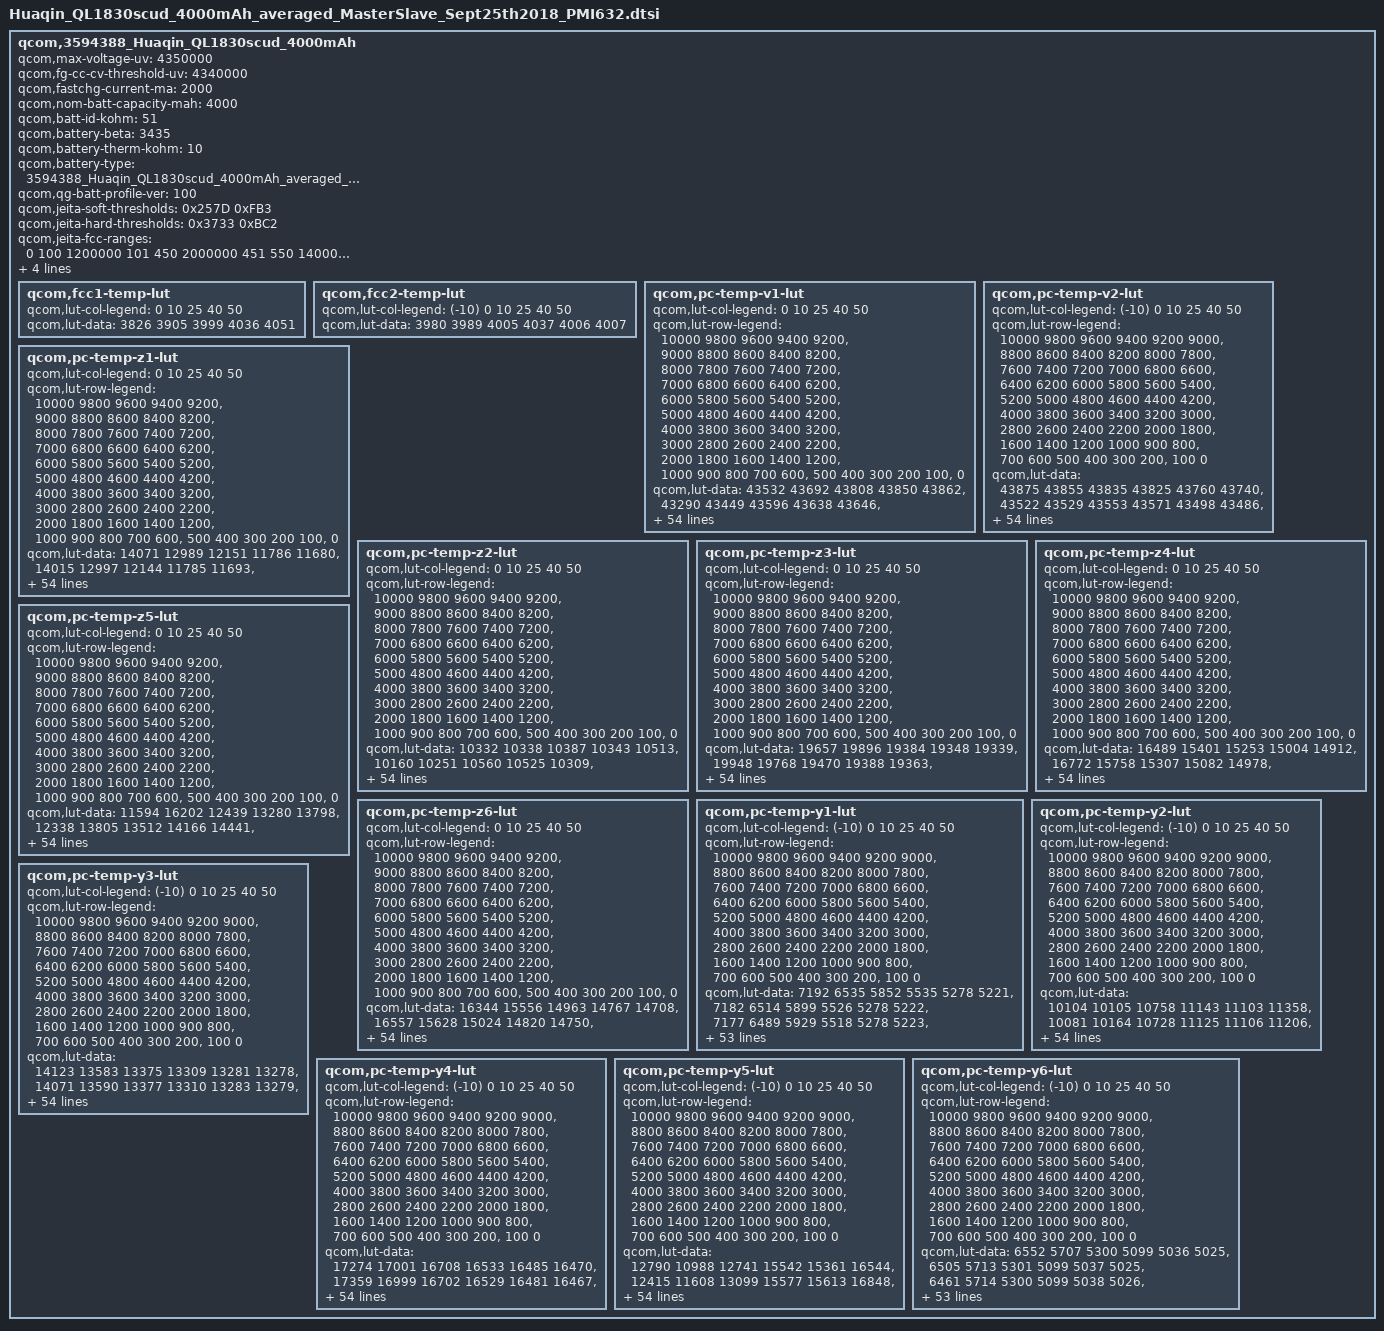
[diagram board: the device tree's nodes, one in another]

qcom,3594388_Huaqin_QL1830scud_4000mAh {
    /* 3594388_Huaqin_QL1830scud_4000mAh_averaged_MasterSlave_Sept25th2018 */
//huaqin add by tangqingyong for jeita and FV 4.35V at 20180928 start
    qcom,max-voltage-uv = <4350000>;
    qcom,fg-cc-cv-threshold-uv = <4340000>;
    qcom,fastchg-current-ma = <2000>;
    qcom,nom-batt-capacity-mah = <4000>;
//huaqin add by tangqingyong for jeita and FV 4.35V at 20180928 end
    qcom,batt-id-kohm = <51>;
    qcom,battery-beta = <3435>;
    qcom,battery-therm-kohm = <10>;
    qcom,battery-type = "3594388_Huaqin_QL1830scud_4000mAh_averaged_MasterSlave_Sept25th2018";
    qcom,qg-batt-profile-ver = <100>;
//huaqin add by tangqingyong for jeita and FV 4.35V at 20180928 start
    /* COOL = 15 DegC, WARM = 45 DegC */
    qcom,jeita-soft-thresholds = <0x257D 0xFB3>;
    /* COLD = 0 DegC, HOT = 55 DegC */
    qcom,jeita-hard-thresholds = <0x3733 0xBC2>;
    qcom,jeita-fcc-ranges = <0   100  1200000
                               101  450  2000000
                               451  550  1400000>;
    qcom,jeita-fv-ranges = <0   450  4350000
                            451 550  4100000>;
/*here step charge do not limit current*/
    qcom,step-chg-ranges = <3500000  4200000  2000000
                            4210000  4350000  2000000>;
//huaqin add by tangqingyong for jeita and FV 4.35V at 20180928 end

	qcom,fcc1-temp-lut {
		qcom,lut-col-legend = <0 10 25 40 50>;
		qcom,lut-data = <3826 3905 3999 4036 4051>;
	};

	qcom,fcc2-temp-lut {
		qcom,lut-col-legend = <(-10) 0 10 25 40 50>;
		qcom,lut-data = <3980 3989 4005 4037 4006 4007>;
	};

	qcom,pc-temp-v1-lut {
		qcom,lut-col-legend = <0 10 25 40 50>;
		qcom,lut-row-legend = <10000 9800 9600 9400 9200>,
			<9000 8800 8600 8400 8200>,
			<8000 7800 7600 7400 7200>,
			<7000 6800 6600 6400 6200>,
			<6000 5800 5600 5400 5200>,
			<5000 4800 4600 4400 4200>,
			<4000 3800 3600 3400 3200>,
			<3000 2800 2600 2400 2200>,
			<2000 1800 1600 1400 1200>,
			<1000 900 800 700 600>,
			<500 400 300 200 100>,
			<0>;
		qcom,lut-data = <43532 43692 43808 43850 43862>,
			<43290 43449 43596 43638 43646>,
			<43052 43210 43371 43421 43428>,
			<42816 42974 43140 43200 43207>,
			<42584 42741 42900 42970 42982>,
			<42355 42509 42659 42735 42752>,
			<42132 42280 42426 42503 42523>,
			<41914 42055 42196 42274 42291>,
			<41702 41835 41968 42045 42061>,
			<41497 41619 41742 41813 41833>,
			<41298 41408 41520 41583 41606>,
			<41101 41202 41304 41362 41386>,
			<40909 41005 41091 41148 41169>,
			<40714 40823 40887 40940 40959>,
			<40493 40635 40687 40737 40753>,
			<40241 40416 40490 40537 40553>,
			<40021 40182 40287 40339 40360>,
			<39866 39991 40090 40145 40174>,
			<39735 39845 39921 39966 39997>,
			<39606 39711 39781 39816 39838>,
			<39480 39571 39633 39660 39677>,
			<39356 39431 39458 39444 39462>,
			<39229 39270 39266 39172 39185>,
			<39101 39052 39055 38959 38967>,
			<38974 38830 38811 38807 38830>,
			<38843 38677 38626 38685 38719>,
			<38717 38557 38534 38588 38617>,
			<38613 38471 38468 38507 38524>,
			<38521 38416 38405 38427 38434>,
			<38446 38373 38345 38347 38340>,
			<38390 38330 38289 38272 38254>,
			<38343 38289 38233 38201 38180>,
			<38302 38249 38179 38135 38113>,
			<38267 38210 38128 38075 38050>,
			<38233 38173 38082 38021 37991>,
			<38198 38135 38038 37969 37933>,
			<38162 38099 37998 37922 37873>,
			<38119 38058 37958 37876 37811>,
			<38064 37992 37896 37812 37737>,
			<37994 37899 37800 37719 37647>,
			<37898 37793 37689 37609 37543>,
			<37751 37669 37570 37490 37424>,
			<37596 37529 37436 37355 37287>,
			<37438 37366 37275 37193 37130>,
			<37315 37231 37141 37059 37000>,
			<37227 37150 37064 36984 36924>,
			<37197 37127 37041 36964 36902>,
			<37175 37106 37027 36949 36890>,
			<37147 37089 37008 36930 36867>,
			<37075 37025 36938 36848 36769>,
			<36791 36734 36648 36540 36448>,
			<36322 36276 36194 36086 35989>,
			<35723 35685 35601 35491 35393>,
			<34901 34868 34789 34677 34575>,
			<33582 33579 33512 33402 33296>,
			<30000 30000 30000 30000 30000>;
	};

	qcom,pc-temp-v2-lut {
		qcom,lut-col-legend = <(-10) 0 10 25 40 50>;
		qcom,lut-row-legend = <10000 9800 9600 9400 9200 9000>,
			<8800 8600 8400 8200 8000 7800>,
			<7600 7400 7200 7000 6800 6600>,
			<6400 6200 6000 5800 5600 5400>,
			<5200 5000 4800 4600 4400 4200>,
			<4000 3800 3600 3400 3200 3000>,
			<2800 2600 2400 2200 2000 1800>,
			<1600 1400 1200 1000 900 800>,
			<700 600 500 400 300 200>,
			<100 0>;
		qcom,lut-data = <43875 43855 43835 43825 43760 43740>,
			<43522 43529 43553 43571 43498 43486>,
			<43194 43225 43285 43323 43245 43238>,
			<42892 42949 43031 43082 43003 43000>,
			<42611 42698 42791 42848 42772 42770>,
			<42356 42456 42555 42616 42543 42542>,
			<42138 42211 42319 42382 42311 42311>,
			<41935 41972 42086 42149 42080 42081>,
			<41699 41746 41858 41920 41853 41853>,
			<41416 41532 41635 41692 41630 41628>,
			<41177 41323 41419 41467 41409 41406>,
			<41043 41122 41214 41247 41190 41189>,
			<40932 40923 41014 41030 40975 40975>,
			<40729 40723 40817 40825 40770 40770>,
			<40343 40525 40622 40629 40574 40570>,
			<39970 40304 40415 40432 40381 40377>,
			<39720 40003 40176 40224 40183 40188>,
			<39513 39679 39925 40023 39990 40007>,
			<39335 39463 39699 39849 39819 39834>,
			<39187 39320 39492 39693 39671 39674>,
			<39044 39182 39297 39512 39505 39499>,
			<38887 39015 39112 39269 39277 39272>,
			<38730 38846 38940 39025 39033 39036>,
			<38585 38701 38787 38846 38847 38853>,
			<38447 38581 38650 38698 38695 38700>,
			<38327 38460 38525 38568 38566 38570>,
			<38232 38314 38410 38453 38454 38459>,
			<38151 38168 38305 38349 38354 38360>,
			<38077 38071 38210 38254 38263 38267>,
			<38008 38005 38123 38166 38179 38178>,
			<37945 37951 38040 38088 38101 38098>,
			<37884 37901 37954 38016 38029 38027>,
			<37826 37856 37875 37950 37959 37961>,
			<37768 37812 37820 37890 37890 37891>,
			<37711 37770 37779 37834 37823 37819>,
			<37654 37726 37741 37774 37750 37736>,
			<37597 37679 37708 37707 37662 37630>,
			<37541 37628 37674 37637 37569 37515>,
			<37485 37569 37623 37567 37484 37420>,
			<37431 37500 37550 37495 37406 37340>,
			<37375 37422 37465 37411 37321 37254>,
			<37316 37323 37366 37309 37220 37154>,
			<37253 37212 37247 37186 37105 37039>,
			<37181 37111 37093 37040 36963 36895>,
			<37095 37013 36973 36921 36859 36800>,
			<36979 36919 36898 36880 36819 36764>,
			<36914 36879 36876 36866 36809 36748>,
			<36847 36837 36852 36845 36787 36730>,
			<36761 36793 36820 36804 36752 36691>,
			<36625 36696 36730 36688 36633 36548>,
			<36374 36443 36443 36332 36277 36169>,
			<35959 35981 35942 35809 35766 35653>,
			<35346 35334 35287 35126 35103 34980>,
			<34454 34432 34374 34178 34194 34076>,
			<32936 32958 32952 32746 32751 32575>,
			<27848 27423 27941 28152 28012 27988>;
	};

	qcom,pc-temp-z1-lut {
		qcom,lut-col-legend = <0 10 25 40 50>;
		qcom,lut-row-legend = <10000 9800 9600 9400 9200>,
			<9000 8800 8600 8400 8200>,
			<8000 7800 7600 7400 7200>,
			<7000 6800 6600 6400 6200>,
			<6000 5800 5600 5400 5200>,
			<5000 4800 4600 4400 4200>,
			<4000 3800 3600 3400 3200>,
			<3000 2800 2600 2400 2200>,
			<2000 1800 1600 1400 1200>,
			<1000 900 800 700 600>,
			<500 400 300 200 100>,
			<0>;
		qcom,lut-data = <14071 12989 12151 11786 11680>,
			<14015 12997 12144 11785 11693>,
			<14021 12993 12142 11786 11693>,
			<14031 12988 12137 11785 11693>,
			<14048 12985 12127 11782 11692>,
			<14066 12988 12118 11778 11691>,
			<14066 12991 12110 11775 11691>,
			<14042 12987 12101 11772 11690>,
			<14023 12968 12093 11770 11689>,
			<14036 12955 12086 11769 11690>,
			<14069 12954 12082 11768 11691>,
			<14081 12955 12082 11768 11691>,
			<14035 12952 12082 11768 11690>,
			<13971 12929 12081 11768 11690>,
			<13945 12903 12076 11766 11689>,
			<13932 12886 12070 11764 11689>,
			<13919 12871 12067 11764 11689>,
			<13897 12867 12063 11763 11690>,
			<13871 12875 12064 11763 11691>,
			<13858 12882 12068 11764 11692>,
			<13857 12880 12073 11766 11692>,
			<13858 12873 12075 11768 11693>,
			<13857 12870 12077 11770 11695>,
			<13849 12884 12080 11772 11697>,
			<13844 12902 12082 11774 11699>,
			<13843 12904 12086 11776 11701>,
			<13842 12900 12091 11779 11703>,
			<13842 12898 12096 11783 11706>,
			<13844 12898 12101 11787 11710>,
			<13844 12900 12106 11790 11713>,
			<13843 12904 12110 11793 11715>,
			<13841 12917 12114 11797 11719>,
			<13841 12927 12118 11800 11723>,
			<13853 12927 12121 11803 11726>,
			<13866 12927 12125 11807 11728>,
			<13867 12928 12129 11810 11730>,
			<13859 12934 12135 11813 11732>,
			<13856 12942 12142 11816 11734>,
			<13871 12946 12149 11819 11737>,
			<13894 12951 12155 11823 11740>,
			<13906 12959 12162 11827 11743>,
			<13914 12974 12169 11832 11746>,
			<13914 12981 12176 11836 11749>,
			<13896 12967 12181 11839 11751>,
			<13872 12958 12191 11844 11755>,
			<13886 12972 12196 11848 11758>,
			<13871 12965 12198 11848 11757>,
			<13855 12970 12192 11849 11758>,
			<13852 12974 12190 11849 11759>,
			<13864 12971 12206 11854 11761>,
			<13904 13012 12209 11861 11769>,
			<13877 13011 12221 11869 11777>,
			<13906 13007 12238 11881 11786>,
			<13899 13083 12267 11898 11803>,
			<13899 13083 12267 11898 11803>,
			<13899 13083 12267 11898 11803>;
	};

	qcom,pc-temp-z2-lut {
		qcom,lut-col-legend = <0 10 25 40 50>;
		qcom,lut-row-legend = <10000 9800 9600 9400 9200>,
			<9000 8800 8600 8400 8200>,
			<8000 7800 7600 7400 7200>,
			<7000 6800 6600 6400 6200>,
			<6000 5800 5600 5400 5200>,
			<5000 4800 4600 4400 4200>,
			<4000 3800 3600 3400 3200>,
			<3000 2800 2600 2400 2200>,
			<2000 1800 1600 1400 1200>,
			<1000 900 800 700 600>,
			<500 400 300 200 100>,
			<0>;
		qcom,lut-data = <10332 10338 10387 10343 10513>,
			<10160 10251 10560 10525 10309>,
			<10134 10214 10958 10995 10515>,
			<10128 10194 11020 11321 10655>,
			<10129 10179 10687 11222 10641>,
			<10132 10164 10415 11021 10602>,
			<10136 10152 10391 10865 10567>,
			<10142 10147 10379 10719 10530>,
			<10147 10143 10367 10650 10505>,
			<10149 10140 10355 10704 10506>,
			<10149 10140 10349 10786 10517>,
			<10152 10142 10367 10789 10496>,
			<10191 10149 10403 10716 10407>,
			<10237 10173 10446 10673 10352>,
			<10224 10203 10555 10732 10371>,
			<10134 10234 10630 10822 10404>,
			<10073 10269 10569 10864 10406>,
			<10118 10288 10455 10884 10357>,
			<10202 10296 10429 10889 10327>,
			<10233 10302 10443 10750 10337>,
			<10239 10306 10463 10582 10360>,
			<10240 10310 10500 10627 10459>,
			<10227 10312 10542 10781 10738>,
			<10193 10313 10550 10836 10870>,
			<10177 10314 10546 10720 10645>,
			<10182 10316 10540 10578 10374>,
			<10194 10319 10518 10514 10361>,
			<10208 10322 10488 10462 10423>,
			<10229 10323 10490 10469 10503>,
			<10247 10324 10540 10645 10653>,
			<10255 10326 10578 10804 10777>,
			<10260 10333 10581 10760 10725>,
			<10268 10341 10581 10643 10562>,
			<10281 10349 10573 10604 10502>,
			<10297 10357 10545 10607 10520>,
			<10319 10363 10527 10611 10555>,
			<10349 10368 10533 10636 10642>,
			<10371 10373 10548 10692 10783>,
			<10331 10384 10569 10744 10833>,
			<10264 10401 10604 10801 10838>,
			<10282 10422 10631 10834 10835>,
			<10438 10446 10641 10833 10815>,
			<10593 10482 10652 10830 10782>,
			<10744 10551 10681 10829 10702>,
			<10485 10891 10812 10854 10652>,
			<10429 11114 10913 10817 10543>,
			<10392 11218 10892 10683 10520>,
			<10359 11280 10891 10631 10550>,
			<10349 11234 10904 10669 10582>,
			<10325 11346 10991 10827 10696>,
			<10354 11461 11235 10793 10509>,
			<10204 11466 11145 10781 10397>,
			<10038 10832 11125 10701 10359>,
			<9915 10646 11036 10604 10253>,
			<9915 10646 11036 10604 10253>,
			<9915 10646 11036 10604 10253>;
	};

	qcom,pc-temp-z3-lut {
		qcom,lut-col-legend = <0 10 25 40 50>;
		qcom,lut-row-legend = <10000 9800 9600 9400 9200>,
			<9000 8800 8600 8400 8200>,
			<8000 7800 7600 7400 7200>,
			<7000 6800 6600 6400 6200>,
			<6000 5800 5600 5400 5200>,
			<5000 4800 4600 4400 4200>,
			<4000 3800 3600 3400 3200>,
			<3000 2800 2600 2400 2200>,
			<2000 1800 1600 1400 1200>,
			<1000 900 800 700 600>,
			<500 400 300 200 100>,
			<0>;
		qcom,lut-data = <19657 19896 19384 19348 19339>,
			<19948 19768 19470 19388 19363>,
			<20037 19767 19513 19422 19399>,
			<20067 19806 19539 19446 19424>,
			<20071 19828 19568 19466 19435>,
			<20073 19832 19585 19484 19442>,
			<20071 19835 19581 19500 19443>,
			<20059 19836 19574 19517 19442>,
			<20048 19836 19571 19525 19440>,
			<20048 19836 19566 19508 19435>,
			<20051 19834 19560 19483 19425>,
			<20050 19829 19549 19476 19412>,
			<20007 19819 19536 19481 19393>,
			<19955 19786 19531 19481 19380>,
			<19981 19756 19538 19461 19376>,
			<20132 19744 19542 19436 19373>,
			<20234 19735 19529 19430 19369>,
			<20168 19728 19507 19428 19362>,
			<20046 19719 19493 19424 19356>,
			<20009 19713 19483 19405 19352>,
			<20016 19714 19479 19385 19349>,
			<20029 19718 19492 19394 19356>,
			<20063 19725 19515 19426 19384>,
			<20132 19763 19523 19438 19398>,
			<20173 19806 19525 19423 19379>,
			<20183 19812 19526 19401 19352>,
			<20190 19808 19518 19384 19340>,
			<20186 19804 19501 19369 19333>,
			<20164 19793 19489 19365 19332>,
			<20137 19778 19480 19377 19370>,
			<20116 19764 19475 19394 19411>,
			<20094 19751 19488 19410 19411>,
			<20070 19742 19509 19428 19403>,
			<20040 19738 19515 19432 19395>,
			<20009 19735 19515 19425 19384>,
			<19979 19731 19515 19415 19377>,
			<19948 19725 19510 19409 19377>,
			<19907 19719 19501 19404 19377>,
			<19788 19714 19496 19399 19377>,
			<19641 19708 19492 19395 19372>,
			<19619 19699 19488 19392 19367>,
			<19736 19683 19483 19392 19369>,
			<19761 19660 19477 19393 19371>,
			<19681 19625 19468 19391 19367>,
			<19393 19528 19442 19382 19355>,
			<19344 19468 19414 19364 19344>,
			<19340 19432 19415 19356 19345>,
			<19334 19418 19398 19355 19336>,
			<19332 19362 19397 19341 19328>,
			<19331 19366 19384 19327 19324>,
			<19340 19400 19338 19333 19335>,
			<19345 19383 19328 19321 19345>,
			<19349 19330 19327 19327 19341>,
			<19355 19330 19324 19324 19343>,
			<19355 19330 19324 19324 19343>,
			<19355 19330 19324 19324 19343>;
	};

	qcom,pc-temp-z4-lut {
		qcom,lut-col-legend = <0 10 25 40 50>;
		qcom,lut-row-legend = <10000 9800 9600 9400 9200>,
			<9000 8800 8600 8400 8200>,
			<8000 7800 7600 7400 7200>,
			<7000 6800 6600 6400 6200>,
			<6000 5800 5600 5400 5200>,
			<5000 4800 4600 4400 4200>,
			<4000 3800 3600 3400 3200>,
			<3000 2800 2600 2400 2200>,
			<2000 1800 1600 1400 1200>,
			<1000 900 800 700 600>,
			<500 400 300 200 100>,
			<0>;
		qcom,lut-data = <16489 15401 15253 15004 14912>,
			<16772 15758 15307 15082 14978>,
			<16538 15761 15262 15049 14960>,
			<16308 15603 15209 15007 14934>,
			<16155 15455 15142 14963 14905>,
			<16023 15360 15080 14916 14872>,
			<15915 15281 15036 14870 14845>,
			<15826 15212 14998 14818 14823>,
			<15749 15152 14962 14786 14804>,
			<15670 15102 14929 14775 14785>,
			<15595 15059 14899 14768 14770>,
			<15561 15025 14872 14759 14768>,
			<15558 15002 14848 14733 14771>,
			<15555 14983 14825 14716 14773>,
			<15516 14971 14792 14720 14764>,
			<15375 14964 14771 14726 14748>,
			<15282 14959 14775 14720 14738>,
			<15309 14950 14786 14705 14731>,
			<15361 14924 14782 14696 14725>,
			<15373 14890 14762 14700 14716>,
			<15318 14862 14751 14712 14710>,
			<15235 14835 14753 14739 14722>,
			<15143 14825 14760 14790 14779>,
			<15031 14844 14783 14832 14827>,
			<14965 14875 14866 14870 14859>,
			<14939 14895 14919 14895 14880>,
			<14922 14914 14916 14895 14881>,
			<14918 14922 14910 14892 14873>,
			<14916 14915 14903 14886 14859>,
			<14915 14902 14891 14856 14801>,
			<14912 14890 14875 14816 14738>,
			<14910 14878 14842 14778 14719>,
			<14907 14866 14801 14739 14709>,
			<14908 14851 14777 14726 14706>,
			<14909 14834 14760 14724 14707>,
			<14910 14822 14751 14724 14709>,
			<14915 14811 14748 14725 14711>,
			<14923 14804 14746 14728 14716>,
			<15018 14801 14749 14734 14722>,
			<15155 14799 14766 14751 14735>,
			<15159 14798 14778 14763 14744>,
			<14989 14797 14771 14756 14737>,
			<14928 14797 14763 14745 14727>,
			<14940 14798 14761 14744 14732>,
			<15037 14783 14741 14731 14728>,
			<15053 14788 14720 14710 14704>,
			<15052 14820 14705 14702 14689>,
			<15052 14828 14706 14680 14673>,
			<15044 14883 14693 14676 14660>,
			<15039 14876 14714 14701 14674>,
			<15035 14851 14797 14733 14701>,
			<15046 14880 14816 14752 14694>,
			<15057 14947 14821 14748 14701>,
			<15063 14956 14832 14755 14701>,
			<15063 14956 14832 14755 14701>,
			<15063 14956 14832 14755 14701>;
	};

	qcom,pc-temp-z5-lut {
		qcom,lut-col-legend = <0 10 25 40 50>;
		qcom,lut-row-legend = <10000 9800 9600 9400 9200>,
			<9000 8800 8600 8400 8200>,
			<8000 7800 7600 7400 7200>,
			<7000 6800 6600 6400 6200>,
			<6000 5800 5600 5400 5200>,
			<5000 4800 4600 4400 4200>,
			<4000 3800 3600 3400 3200>,
			<3000 2800 2600 2400 2200>,
			<2000 1800 1600 1400 1200>,
			<1000 900 800 700 600>,
			<500 400 300 200 100>,
			<0>;
		qcom,lut-data = <11594 16202 12439 13280 13798>,
			<12338 13805 13512 14166 14441>,
			<12643 13595 14108 14968 15902>,
			<12811 13973 14517 15446 16951>,
			<12919 14317 15174 15985 17391>,
			<12994 14537 15679 16768 17731>,
			<13046 14735 15782 17806 17931>,
			<13079 15000 15808 19396 18088>,
			<13116 15351 15943 20335 18182>,
			<13223 15731 16253 20415 18291>,
			<13395 16220 16625 20399 18421>,
			<13454 16702 17098 21091 18110>,
			<13173 16758 17632 24575 16890>,
			<12828 16337 18290 26593 16121>,
			<13200 15984 20139 24440 16376>,
			<15124 16156 21442 21550 16832>,
			<16435 16607 20576 21621 16999>,
			<15668 16959 18952 23391 16945>,
			<14254 17255 18655 24448 17001>,
			<13845 17696 19373 22646 17349>,
			<14174 18563 20574 20453 18060>,
			<14814 20387 25748 25729 21894>,
			<16405 23435 33409 40473 33257>,
			<20053 35040 36099 45848 38667>,
			<24073 47609 37156 36535 30605>,
			<29151 48538 37572 25309 20036>,
			<33938 44480 33934 20707 16808>,
			<35638 39858 27221 17661 15163>,
			<36400 35388 23423 16658 14800>,
			<36580 31040 20837 16802 17625>,
			<35355 28379 19705 17420 21310>,
			<32731 26386 20882 19607 22963>,
			<30281 25423 23392 23792 24070>,
			<27906 25586 25827 26393 24866>,
			<25700 25975 28728 28117 25598>,
			<24014 26221 30343 29044 26276>,
			<22446 26355 30320 28824 27106>,
			<20729 26507 29989 28091 28141>,
			<18108 27042 29380 26870 28073>,
			<15582 27998 27967 23900 24186>,
			<15415 28276 26512 21658 20759>,
			<17853 26526 25386 21411 20720>,
			<18578 24460 24378 21250 20901>,
			<17343 22897 23032 20497 19649>,
			<13553 21347 23052 20435 18369>,
			<12790 18779 21766 19755 18029>,
			<12691 15897 22041 18912 18868>,
			<12588 15219 19269 20045 18655>,
			<12592 13668 19537 18483 19514>,
			<12663 13825 17904 15823 17277>,
			<12898 14811 13783 14376 15113>,
			<12801 13979 13125 13275 15562>,
			<12658 12617 12921 13318 14752>,
			<12561 12469 12644 12952 14451>,
			<12561 12469 12644 12952 14451>,
			<12561 12469 12644 12952 14451>;
	};

	qcom,pc-temp-z6-lut {
		qcom,lut-col-legend = <0 10 25 40 50>;
		qcom,lut-row-legend = <10000 9800 9600 9400 9200>,
			<9000 8800 8600 8400 8200>,
			<8000 7800 7600 7400 7200>,
			<7000 6800 6600 6400 6200>,
			<6000 5800 5600 5400 5200>,
			<5000 4800 4600 4400 4200>,
			<4000 3800 3600 3400 3200>,
			<3000 2800 2600 2400 2200>,
			<2000 1800 1600 1400 1200>,
			<1000 900 800 700 600>,
			<500 400 300 200 100>,
			<0>;
		qcom,lut-data = <16344 15556 14963 14767 14708>,
			<16557 15628 15024 14820 14750>,
			<16483 15623 15031 14826 14761>,
			<16399 15561 15026 14826 14765>,
			<16326 15499 15007 14819 14760>,
			<16252 15454 14986 14806 14749>,
			<16192 15414 14965 14794 14739>,
			<16140 15379 14943 14781 14730>,
			<16095 15349 14924 14767 14720>,
			<16059 15323 14906 14754 14709>,
			<16029 15302 14889 14741 14698>,
			<15998 15283 14871 14730 14689>,
			<15958 15260 14854 14721 14681>,
			<15926 15230 14841 14713 14673>,
			<15923 15204 14831 14703 14666>,
			<15930 15191 14822 14695 14659>,
			<15935 15182 14814 14688 14651>,
			<15914 15171 14807 14681 14644>,
			<15870 15154 14798 14674 14638>,
			<15834 15137 14784 14666 14632>,
			<15806 15127 14777 14661 14627>,
			<15781 15120 14783 14674 14638>,
			<15761 15118 14797 14716 14680>,
			<15744 15146 14818 14737 14703>,
			<15732 15184 14855 14743 14703>,
			<15725 15197 14876 14745 14702>,
			<15719 15204 14871 14742 14698>,
			<15711 15207 14861 14733 14692>,
			<15699 15200 14852 14725 14685>,
			<15685 15187 14843 14718 14681>,
			<15674 15175 14835 14712 14676>,
			<15663 15165 14828 14706 14669>,
			<15652 15156 14822 14699 14661>,
			<15640 15148 14816 14694 14655>,
			<15627 15141 14811 14689 14650>,
			<15614 15135 14806 14686 14647>,
			<15599 15131 14801 14683 14648>,
			<15585 15127 14797 14682 14650>,
			<15573 15125 14798 14682 14652>,
			<15563 15124 14804 14687 14655>,
			<15555 15122 14808 14691 14656>,
			<15548 15117 14805 14689 14655>,
			<15537 15110 14799 14685 14652>,
			<15506 15095 14794 14684 14652>,
			<15402 15043 14775 14674 14645>,
			<15383 15017 14752 14656 14629>,
			<15378 15013 14746 14649 14623>,
			<15374 15010 14737 14639 14611>,
			<15371 15006 14732 14629 14601>,
			<15375 15009 14736 14633 14606>,
			<15385 15021 14750 14652 14625>,
			<15400 15031 14756 14657 14630>,
			<15421 15040 14762 14661 14633>,
			<15446 15058 14771 14666 14638>,
			<15446 15058 14771 14666 14638>,
			<15446 15058 14771 14666 14638>;
	};

	qcom,pc-temp-y1-lut {
		qcom,lut-col-legend = <(-10) 0 10 25 40 50>;
		qcom,lut-row-legend = <10000 9800 9600 9400 9200 9000>,
			<8800 8600 8400 8200 8000 7800>,
			<7600 7400 7200 7000 6800 6600>,
			<6400 6200 6000 5800 5600 5400>,
			<5200 5000 4800 4600 4400 4200>,
			<4000 3800 3600 3400 3200 3000>,
			<2800 2600 2400 2200 2000 1800>,
			<1600 1400 1200 1000 900 800>,
			<700 600 500 400 300 200>,
			<100 0>;
		qcom,lut-data = <7192 6535 5852 5535 5278 5221>,
			<7182 6514 5899 5526 5278 5222>,
			<7177 6489 5929 5518 5278 5223>,
			<7176 6464 5946 5509 5277 5223>,
			<7176 6443 5953 5502 5277 5223>,
			<7176 6430 5955 5495 5276 5223>,
			<7179 6424 5942 5488 5275 5222>,
			<7184 6421 5922 5482 5274 5221>,
			<7180 6421 5919 5476 5272 5220>,
			<7164 6425 5922 5469 5271 5220>,
			<7152 6429 5924 5464 5270 5219>,
			<7150 6428 5917 5461 5269 5219>,
			<7150 6426 5906 5459 5268 5219>,
			<7159 6424 5904 5456 5267 5218>,
			<7186 6424 5905 5454 5266 5219>,
			<7204 6425 5906 5452 5266 5219>,
			<7193 6432 5911 5453 5267 5219>,
			<7172 6442 5917 5454 5267 5219>,
			<7168 6443 5917 5455 5268 5219>,
			<7185 6434 5917 5455 5269 5220>,
			<7200 6427 5917 5456 5270 5221>,
			<7190 6426 5917 5458 5270 5221>,
			<7168 6426 5918 5460 5271 5222>,
			<7162 6426 5920 5463 5272 5223>,
			<7161 6431 5922 5465 5274 5224>,
			<7158 6434 5923 5468 5276 5225>,
			<7146 6434 5924 5471 5278 5227>,
			<7126 6433 5924 5475 5281 5229>,
			<7120 6432 5925 5479 5283 5231>,
			<7137 6427 5930 5483 5285 5233>,
			<7154 6425 5933 5487 5288 5235>,
			<7152 6428 5938 5491 5291 5237>,
			<7149 6433 5946 5495 5293 5240>,
			<7145 6436 5947 5500 5296 5242>,
			<7140 6434 5944 5504 5299 5244>,
			<7135 6430 5942 5508 5302 5246>,
			<7131 6418 5945 5512 5304 5248>,
			<7125 6401 5950 5515 5307 5250>,
			<7116 6396 5951 5520 5309 5251>,
			<7093 6398 5951 5525 5311 5253>,
			<7075 6400 5953 5529 5313 5255>,
			<7071 6397 5957 5532 5316 5256>,
			<7072 6392 5960 5537 5319 5258>,
			<7098 6399 5964 5549 5323 5259>,
			<7112 6427 5969 5553 5327 5264>,
			<7124 6440 5987 5554 5329 5266>,
			<7148 6435 5999 5555 5329 5267>,
			<7173 6454 5998 5560 5330 5266>,
			<7159 6487 5983 5563 5330 5266>,
			<7152 6469 5981 5565 5330 5268>,
			<7141 6454 5988 5570 5334 5271>,
			<7149 6472 5999 5582 5341 5277>,
			<7193 6492 6003 5604 5351 5286>,
			<7242 6491 6028 5629 5364 5297>,
			<7242 6491 6028 5629 5364 5297>,
			<7242 6491 6028 5629 5364 5297>;
	};

	qcom,pc-temp-y2-lut {
		qcom,lut-col-legend = <(-10) 0 10 25 40 50>;
		qcom,lut-row-legend = <10000 9800 9600 9400 9200 9000>,
			<8800 8600 8400 8200 8000 7800>,
			<7600 7400 7200 7000 6800 6600>,
			<6400 6200 6000 5800 5600 5400>,
			<5200 5000 4800 4600 4400 4200>,
			<4000 3800 3600 3400 3200 3000>,
			<2800 2600 2400 2200 2000 1800>,
			<1600 1400 1200 1000 900 800>,
			<700 600 500 400 300 200>,
			<100 0>;
		qcom,lut-data = <10104 10105 10758 11143 11103 11358>,
			<10081 10164 10728 11125 11106 11206>,
			<10078 10212 10708 11101 11113 11097>,
			<10090 10248 10695 11076 11120 11026>,
			<10113 10270 10689 11055 11127 10986>,
			<10144 10278 10687 11044 11130 10974>,
			<10182 10264 10692 11040 11129 11012>,
			<10234 10242 10703 11038 11128 11071>,
			<10320 10243 10714 11045 11137 11082>,
			<10486 10284 10727 11077 11171 11081>,
			<10587 10346 10734 11109 11197 11081>,
			<10573 10477 10723 11150 11206 11104>,
			<10547 10634 10707 11187 11213 11142>,
			<10553 10660 10725 11184 11219 11155>,
			<10636 10632 10830 11160 11226 11155>,
			<10747 10612 10896 11149 11237 11161>,
			<10885 10634 10894 11176 11342 11211>,
			<11026 10685 10891 11217 11495 11297>,
			<11013 10743 10893 11247 11547 11380>,
			<10669 10820 10910 11276 11570 11475>,
			<10377 10903 10933 11285 11578 11519>,
			<10149 11002 10970 11250 11503 11450>,
			<9789 11095 11016 11212 11388 11331>,
			<9695 11107 11054 11222 11355 11260>,
			<9687 11066 11087 11261 11344 11206>,
			<9682 11036 11119 11294 11340 11184>,
			<9677 11067 11159 11316 11383 11305>,
			<9672 11121 11194 11337 11449 11473>,
			<9670 11132 11201 11365 11486 11485>,
			<9669 11117 11200 11396 11517 11415>,
			<9668 11095 11201 11422 11552 11374>,
			<9667 11066 11209 11446 11611 11446>,
			<9666 11015 11219 11461 11666 11566>,
			<9666 10853 11216 11457 11662 11637>,
			<9665 10208 11192 11445 11618 11689>,
			<9664 9725 11166 11431 11582 11709>,
			<9663 9694 11140 11411 11547 11587>,
			<9662 9681 11114 11390 11502 11411>,
			<9662 9674 11094 11372 11466 11369>,
			<9661 9670 11079 11353 11432 11365>,
			<9661 9667 11059 11335 11414 11371>,
			<9661 9665 11023 11321 11409 11385>,
			<9660 9663 10976 11291 11402 11391>,
			<9660 9661 10921 11230 11373 11252>,
			<9660 9660 10839 11200 11205 11020>,
			<9659 9660 10844 11189 11181 11019>,
			<9659 9660 10803 11198 11172 11019>,
			<9659 9659 10773 11187 11140 11035>,
			<9658 9658 10738 11162 11150 11042>,
			<9658 9658 10712 11129 11144 11045>,
			<9657 9657 10618 11140 11138 10951>,
			<9657 9656 10406 11056 11093 10841>,
			<9655 9655 9737 10942 11015 10827>,
			<9653 9655 9679 10857 10946 10820>,
			<9653 9655 9679 10857 10946 10820>,
			<9653 9655 9679 10857 10946 10820>;
	};

	qcom,pc-temp-y3-lut {
		qcom,lut-col-legend = <(-10) 0 10 25 40 50>;
		qcom,lut-row-legend = <10000 9800 9600 9400 9200 9000>,
			<8800 8600 8400 8200 8000 7800>,
			<7600 7400 7200 7000 6800 6600>,
			<6400 6200 6000 5800 5600 5400>,
			<5200 5000 4800 4600 4400 4200>,
			<4000 3800 3600 3400 3200 3000>,
			<2800 2600 2400 2200 2000 1800>,
			<1600 1400 1200 1000 900 800>,
			<700 600 500 400 300 200>,
			<100 0>;
		qcom,lut-data = <14123 13583 13375 13309 13281 13278>,
			<14071 13590 13377 13310 13283 13279>,
			<14004 13594 13382 13311 13284 13281>,
			<13939 13595 13387 13312 13286 13282>,
			<13888 13596 13392 13313 13287 13284>,
			<13867 13595 13393 13314 13289 13285>,
			<13876 13585 13393 13315 13290 13286>,
			<13889 13569 13393 13317 13291 13288>,
			<13877 13573 13393 13317 13293 13289>,
			<13782 13608 13392 13316 13298 13290>,
			<13693 13633 13392 13316 13301 13291>,
			<13652 13588 13398 13318 13302 13293>,
			<13623 13514 13408 13320 13302 13295>,
			<13619 13502 13409 13320 13303 13296>,
			<13628 13528 13409 13320 13307 13298>,
			<13635 13545 13408 13320 13310 13299>,
			<13588 13526 13406 13320 13309 13301>,
			<13502 13492 13403 13321 13306 13303>,
			<13471 13477 13399 13324 13304 13302>,
			<13462 13473 13390 13328 13300 13297>,
			<13459 13467 13381 13330 13297 13291>,
			<13466 13446 13373 13324 13294 13287>,
			<13480 13418 13365 13315 13291 13283>,
			<13483 13412 13361 13311 13290 13281>,
			<13478 13413 13358 13309 13288 13281>,
			<13473 13413 13356 13307 13287 13280>,
			<13471 13397 13353 13307 13287 13282>,
			<13470 13368 13351 13306 13287 13284>,
			<13473 13361 13351 13307 13287 13284>,
			<13487 13361 13354 13308 13287 13281>,
			<13505 13361 13356 13308 13288 13279>,
			<13523 13364 13352 13309 13290 13280>,
			<13544 13371 13347 13310 13292 13281>,
			<13567 13380 13346 13312 13292 13283>,
			<13591 13395 13350 13314 13291 13284>,
			<13618 13412 13354 13314 13290 13285>,
			<13647 13428 13360 13314 13288 13284>,
			<13679 13446 13366 13312 13288 13282>,
			<13716 13467 13366 13312 13288 13282>,
			<13761 13495 13366 13311 13288 13282>,
			<13810 13527 13365 13311 13288 13283>,
			<13859 13559 13365 13311 13289 13285>,
			<13911 13597 13364 13311 13289 13285>,
			<13962 13659 13357 13309 13289 13282>,
			<13998 13717 13356 13306 13288 13284>,
			<13908 13657 13344 13310 13292 13289>,
			<13877 13680 13350 13312 13298 13290>,
			<13953 13728 13356 13316 13299 13296>,
			<14022 13800 13370 13322 13308 13299>,
			<14103 13872 13380 13330 13308 13297>,
			<14194 13952 13374 13316 13298 13290>,
			<14304 14047 13378 13319 13299 13290>,
			<14508 14176 13425 13335 13307 13295>,
			<15053 14321 13506 13352 13314 13305>,
			<15053 14321 13506 13352 13314 13305>,
			<15053 14321 13506 13352 13314 13305>;
	};

	qcom,pc-temp-y4-lut {
		qcom,lut-col-legend = <(-10) 0 10 25 40 50>;
		qcom,lut-row-legend = <10000 9800 9600 9400 9200 9000>,
			<8800 8600 8400 8200 8000 7800>,
			<7600 7400 7200 7000 6800 6600>,
			<6400 6200 6000 5800 5600 5400>,
			<5200 5000 4800 4600 4400 4200>,
			<4000 3800 3600 3400 3200 3000>,
			<2800 2600 2400 2200 2000 1800>,
			<1600 1400 1200 1000 900 800>,
			<700 600 500 400 300 200>,
			<100 0>;
		qcom,lut-data = <17274 17001 16708 16533 16485 16470>,
			<17359 16999 16702 16529 16481 16467>,
			<17411 17000 16699 16527 16479 16466>,
			<17438 17005 16698 16527 16479 16465>,
			<17448 17013 16697 16529 16480 16465>,
			<17449 17022 16698 16531 16483 16466>,
			<17365 17040 16700 16535 16487 16467>,
			<17229 17059 16704 16541 16492 16469>,
			<17209 17046 16711 16549 16494 16472>,
			<17278 16954 16725 16561 16495 16477>,
			<17364 16891 16733 16574 16495 16482>,
			<17456 16995 16732 16584 16503 16487>,
			<17543 17165 16729 16595 16516 16491>,
			<17512 17191 16739 16612 16525 16496>,
			<17199 17124 16789 16636 16531 16504>,
			<16969 17039 16821 16656 16539 16512>,
			<17005 16947 16793 16673 16553 16519>,
			<17076 16858 16741 16684 16572 16528>,
			<17103 16834 16700 16684 16595 16545>,
			<17104 16829 16662 16676 16627 16578>,
			<17100 16825 16637 16662 16643 16595>,
			<17085 16820 16626 16602 16599 16565>,
			<17053 16814 16618 16539 16529 16516>,
			<17030 16799 16613 16522 16502 16493>,
			<17005 16759 16610 16514 16488 16480>,
			<16990 16728 16609 16512 16483 16475>,
			<16995 16722 16610 16517 16488 16477>,
			<17004 16718 16611 16524 16497 16481>,
			<17007 16718 16610 16531 16508 16488>,
			<17004 16721 16600 16540 16522 16505>,
			<17001 16725 16593 16550 16533 16521>,
			<16999 16726 16592 16563 16540 16535>,
			<16997 16727 16592 16573 16545 16545>,
			<16998 16735 16594 16576 16547 16546>,
			<17004 16777 16604 16578 16549 16542>,
			<17014 16816 16615 16578 16550 16536>,
			<17030 16830 16627 16567 16532 16514>,
			<17054 16839 16639 16556 16507 16489>,
			<17079 16841 16645 16552 16502 16484>,
			<17106 16836 16649 16550 16501 16483>,
			<17133 16831 16651 16548 16501 16483>,
			<17159 16825 16649 16546 16502 16483>,
			<17179 16820 16645 16541 16503 16482>,
			<17185 16816 16630 16531 16488 16473>,
			<17180 16819 16625 16519 16484 16465>,
			<17028 16799 16627 16521 16489 16470>,
			<16978 16802 16640 16540 16494 16487>,
			<16985 16832 16666 16562 16517 16504>,
			<16996 16850 16688 16584 16532 16527>,
			<16996 16870 16701 16582 16531 16518>,
			<16980 16846 16690 16546 16486 16472>,
			<16961 16819 16681 16544 16483 16474>,
			<16981 16820 16730 16544 16484 16478>,
			<17167 16838 16765 16576 16510 16507>,
			<17167 16838 16765 16576 16510 16507>,
			<17167 16838 16765 16576 16510 16507>;
	};

	qcom,pc-temp-y5-lut {
		qcom,lut-col-legend = <(-10) 0 10 25 40 50>;
		qcom,lut-row-legend = <10000 9800 9600 9400 9200 9000>,
			<8800 8600 8400 8200 8000 7800>,
			<7600 7400 7200 7000 6800 6600>,
			<6400 6200 6000 5800 5600 5400>,
			<5200 5000 4800 4600 4400 4200>,
			<4000 3800 3600 3400 3200 3000>,
			<2800 2600 2400 2200 2000 1800>,
			<1600 1400 1200 1000 900 800>,
			<700 600 500 400 300 200>,
			<100 0>;
		qcom,lut-data = <12790 10988 12741 15542 15361 16544>,
			<12415 11608 13099 15577 15613 16848>,
			<12241 12235 13536 15540 15705 17012>,
			<12238 12786 13961 15447 15676 17070>,
			<12374 13180 14283 15312 15561 17055>,
			<12622 13332 14410 15150 15399 17001>,
			<14072 13206 14356 14953 15070 16863>,
			<16170 13005 14261 14707 14709 16623>,
			<16251 13360 14202 14363 14792 16306>,
			<14103 15585 14149 13867 15523 15813>,
			<12595 17095 14165 13622 15981 15429>,
			<13242 15645 14681 13636 15442 15364>,
			<14765 13265 15581 13669 14633 15458>,
			<16530 13601 16224 13634 14523 15441>,
			<19132 18560 16675 13508 14684 15147>,
			<20694 22014 17336 13515 14780 14967>,
			<18435 19733 19607 14269 14569 15012>,
			<14341 15872 22283 15704 14258 15044>,
			<13295 15199 22390 18268 14272 14909>,
			<13515 16318 20590 22543 14717 14277>,
			<13700 17111 18864 24227 15380 13906>,
			<13591 16701 17732 22994 17146 15180>,
			<13353 15997 16888 21188 19156 17016>,
			<13122 16191 16670 19870 19344 17242>,
			<12754 18422 16595 18657 18647 16837>,
			<12401 20045 16569 17901 17853 16587>,
			<12154 17942 16616 17409 17022 16741>,
			<11956 14206 16730 17137 16291 16956>,
			<11914 13222 17219 17203 16131 16681>,
			<11929 13146 18983 17437 16173 15333>,
			<11945 13117 20042 17660 16309 14551>,
			<11993 13316 18821 18049 17152 14809>,
			<12071 13681 17089 18614 18175 15374>,
			<12083 13715 16844 19710 18299 16224>,
			<12047 13310 17075 21265 18198 17690>,
			<11993 13006 17375 21645 18110 18441>,
			<11893 13062 18205 20790 18145 18404>,
			<11758 13194 19190 19676 18217 18272>,
			<11723 13329 19156 18780 18032 18055>,
			<11764 13557 18212 17926 17272 17635>,
			<11828 13709 17497 17365 16580 17358>,
			<11924 13332 17354 17013 16142 17377>,
			<12089 12820 17139 16676 15957 17356>,
			<12292 12843 15634 16289 16715 16755>,
			<12567 12831 14968 15385 15996 17008>,
			<12803 12859 13897 15735 15208 16508>,
			<12949 12956 14091 15003 16083 15453>,
			<13156 12793 13968 14538 15185 16519>,
			<13332 13210 14616 14875 16825 16758>,
			<13481 13291 15099 16292 17312 16588>,
			<13334 13302 14431 14926 16564 16300>,
			<13011 12941 13910 15275 17122 16277>,
			<12427 12791 13376 18051 20069 18336>,
			<11586 12857 13617 22437 24019 25452>,
			<11586 12857 13617 22437 24019 25452>,
			<11586 12857 13617 22437 24019 25452>;
	};

	qcom,pc-temp-y6-lut {
		qcom,lut-col-legend = <(-10) 0 10 25 40 50>;
		qcom,lut-row-legend = <10000 9800 9600 9400 9200 9000>,
			<8800 8600 8400 8200 8000 7800>,
			<7600 7400 7200 7000 6800 6600>,
			<6400 6200 6000 5800 5600 5400>,
			<5200 5000 4800 4600 4400 4200>,
			<4000 3800 3600 3400 3200 3000>,
			<2800 2600 2400 2200 2000 1800>,
			<1600 1400 1200 1000 900 800>,
			<700 600 500 400 300 200>,
			<100 0>;
		qcom,lut-data = <6552 5707 5300 5099 5036 5025>,
			<6505 5713 5301 5099 5037 5025>,
			<6461 5714 5300 5099 5038 5026>,
			<6419 5713 5300 5099 5039 5027>,
			<6381 5710 5299 5099 5041 5028>,
			<6348 5706 5297 5099 5042 5029>,
			<6322 5698 5295 5100 5044 5031>,
			<6298 5690 5292 5102 5046 5033>,
			<6266 5684 5291 5104 5049 5034>,
			<6218 5679 5292 5106 5052 5036>,
			<6191 5677 5292 5109 5055 5039>,
			<6196 5676 5294 5113 5058 5041>,
			<6203 5675 5296 5117 5060 5044>,
			<6196 5674 5301 5121 5064 5046>,
			<6137 5672 5312 5127 5068 5050>,
			<6081 5668 5319 5133 5073 5053>,
			<6058 5638 5311 5138 5076 5056>,
			<6043 5591 5295 5141 5079 5060>,
			<6036 5581 5280 5142 5084 5064>,
			<6033 5581 5263 5142 5090 5069>,
			<6031 5581 5250 5141 5093 5071>,
			<6026 5574 5240 5120 5078 5060>,
			<6019 5562 5234 5095 5056 5042>,
			<6016 5560 5231 5088 5046 5034>,
			<6013 5563 5230 5084 5041 5029>,
			<6011 5565 5229 5083 5039 5028>,
			<6018 5562 5230 5084 5041 5029>,
			<6036 5558 5231 5086 5044 5032>,
			<6053 5559 5233 5089 5047 5035>,
			<6068 5576 5236 5093 5051 5038>,
			<6086 5598 5238 5097 5055 5041>,
			<6107 5619 5239 5101 5059 5045>,
			<6130 5642 5240 5106 5062 5050>,
			<6154 5667 5244 5109 5063 5051>,
			<6178 5694 5254 5112 5063 5051>,
			<6204 5723 5266 5113 5062 5050>,
			<6235 5754 5279 5110 5057 5043>,
			<6269 5787 5294 5107 5049 5034>,
			<6306 5825 5306 5106 5048 5033>,
			<6349 5868 5317 5106 5048 5034>,
			<6394 5914 5328 5106 5049 5035>,
			<6439 5959 5343 5107 5050 5036>,
			<6484 6007 5357 5107 5051 5036>,
			<6536 6066 5369 5104 5047 5031>,
			<6563 6124 5388 5101 5046 5031>,
			<6472 6075 5368 5104 5050 5037>,
			<6439 6095 5392 5111 5057 5042>,
			<6502 6146 5421 5122 5064 5052>,
			<6562 6214 5457 5133 5074 5061>,
			<6627 6281 5487 5138 5074 5056>,
			<6701 6344 5506 5119 5054 5039>,
			<6794 6421 5550 5125 5055 5040>,
			<6987 6533 5637 5141 5062 5046>,
			<7544 6669 5755 5169 5077 5064>,
			<7544 6669 5755 5169 5077 5064>,
			<7544 6669 5755 5169 5077 5064>;
	};

};
